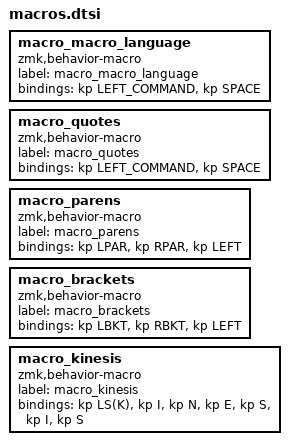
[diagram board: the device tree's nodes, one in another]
macro_macro_language: macro_macro_language{
compatible = "zmk,behavior-macro";
label = "macro_macro_language";
#binding-cells = <0>;
bindings = <&kp LEFT_COMMAND>, <&kp SPACE>;
};
macro_quotes: macro_quotes{
compatible = "zmk,behavior-macro";
label = "macro_quotes";
#binding-cells = <0>;
bindings = <&kp LEFT_COMMAND>, <&kp SPACE>;
};
macro_parens: macro_parens{
compatible = "zmk,behavior-macro";
label = "macro_parens";
#binding-cells = <0>;
bindings = <&kp LPAR>, <&kp RPAR>, <&kp LEFT>;
};
macro_brackets: macro_brackets{
compatible = "zmk,behavior-macro";
label = "macro_brackets";
#binding-cells = <0>;
bindings = <&kp LBKT>, <&kp RBKT>, <&kp LEFT>;
};
macro_kinesis: macro_kinesis{
compatible = "zmk,behavior-macro";
label = "macro_kinesis";
#binding-cells = <0>;
bindings = <&kp LS(K)>, <&kp I>, <&kp N>, <&kp E>, <&kp S>, <&kp I>, <&kp S>;
};
macro_kinesis: macro_kinesis{
compatible = "zmk,behavior-macro";
label = "macro_kinesis";
#binding-cells = <0>;
bindings = <&kp LS(K)>, <&kp I>, <&kp N>, <&kp E>, <&kp S>, <&kp I>, <&kp S>;
};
